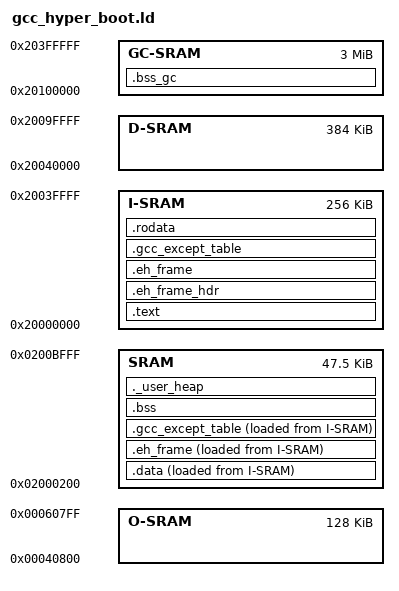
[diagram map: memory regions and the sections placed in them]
/*
 * Copyright (C) 2017-2019 Alibaba Group Holding Limited
 */

/******************************************************************************
 * @file     gcc_csky.ld
 * @brief    csky linker file
 * @version  V1.0
 * @date     02. June 2017
 ******************************************************************************/
MEMORY
{
	I-SRAM : ORIGIN = 0x20000000 , LENGTH = 0x40000   /* I-SRAM  128KB */
	D-SRAM : ORIGIN = 0x20040000 , LENGTH = 0x60000   /* D-SRAM  128KB */
	GC-SRAM : ORIGIN = 0x20100000 , LENGTH = 0x300000   /* GC-SRAM  3MB */
	O-SRAM : ORIGIN = 0x40800 , LENGTH = 0x20000   /* off-chip SRAM 8MB */
	SRAM   : ORIGIN = 0x02000200 , LENGTH = 0xBE00   /* on-chip SRAM 128KB */
}

__min_heap_size = 0x0000;

REGION_ALIAS("REGION_TEXT",    I-SRAM);
REGION_ALIAS("REGION_RODATA",  I-SRAM);
REGION_ALIAS("REGION_DATA",    SRAM);
REGION_ALIAS("REGION_BSS",     SRAM);
REGION_ALIAS("REGION_GC",      GC-SRAM);

ENTRY(Reset_Handler)
SECTIONS
{
 .text : {
  . = ALIGN(0x4) ;
  KEEP(*startup.o(*.text*))
  KEEP (*(SORT(.version)))
  KEEP (*(SORT(.compiledate)))
  KEEP (*(SORT(.compiletime)))
  . = ALIGN(0x4) ;
  __stext = . ;
  *(.text)
  *(.text*)
  *(.text.*)
  *(.gnu.warning)
  *(.stub)
  *(.gnu.linkonce.t*)
  *(.glue_7t)
  *(.glue_7)
  *(.jcr)
  KEEP (*(.init))
  KEEP (*(.fini))
  . = ALIGN (4) ;
  PROVIDE(__ctbp = .);
  *(.call_table_data)
  *(.call_table_text)
  . = ALIGN(0x10) ;
  __etext = . ;
  /* section information for usbh class */
  . = ALIGN(4);
  __usbh_class_info_start__ = .;
  KEEP(*(.usbh_class_info))
  __usbh_class_info_end__ = .;
 } > REGION_TEXT
 .eh_frame_hdr : {
  *(.eh_frame_hdr)
 } > REGION_TEXT
 .eh_frame : ONLY_IF_RO {
  KEEP (*(.eh_frame))
 } > REGION_TEXT
 .gcc_except_table : ONLY_IF_RO {
  *(.gcc_except_table .gcc_except_table.*)
 } > REGION_TEXT
 .rodata : {
  . = ALIGN(0x4) ;
  __srodata = .;
  *(.rdata)
  *(.rdata*)
  *(.rdata1)
  *(.rdata.*)
  *(.rodata)
  *(.rodata1)
  *(.rodata*)
  *(.rodata.*)
  *(.rodata.str1.4)
  *(.srodata*)
  . = ALIGN(0x4) ;
  __ctor_start__ = .;
  KEEP (*(SORT(.ctors.*)))
  KEEP (*(.ctors))
  __ctor_end__ = .;
  KEEP (*(SORT(.dtors.*)))
  KEEP (*(.dtors))
  __dtor_end__ = .;
  . = ALIGN(0x4) ;
  __erodata = .;
  __rodata_end__ = .;
 } > REGION_RODATA
 .data : {
  . = ALIGN(0x4) ;
  __sdata = . ;
  __data_start__ = . ;
  data_start = . ;
  KEEP(*startup.o(*.vectors*))
  *(.got.plt)
  *(.got)
  *(.gnu.linkonce.r*)
  *(.data)
  *(.data*)
  *(.data1)
  *(.data.*)
  *(.gnu.linkonce.d*)
  *(.data1)
  *(.gcc_except_table)
  *(.gcc_except_table*)
  __start_init_call = .;
  *(.initcall.init)
  __stop_init_call = .;
  __start_cmd = .;
  *(.bootloaddata.cmd)
  . = ALIGN(4) ;
  __stop_cmd = .;
  __global_pointer$ = .;
  *(.sdata)
  *(.sdata.*)
  *(.sdata2.*)
  *(.gnu.linkonce.s.*)
  *(__libc_atexit)
  *(__libc_subinit)
  *(__libc_subfreeres)
  *(.note.ABI-tag)
  __edata = .;
  __data_end__ = .;
  . = ALIGN(0x4) ;
 } > REGION_DATA AT > REGION_RODATA
 .eh_frame : ONLY_IF_RW {
  KEEP (*(.eh_frame))
 } > REGION_DATA AT > REGION_RODATA
 .gcc_except_table : ONLY_IF_RW {
  *(.gcc_except_table .gcc_except_table.*)
  __edata = .;
  __data_end__ = .;
 } > REGION_DATA AT > REGION_RODATA
 .bss : {
  . = ALIGN(0x4) ;
  __sbss = ALIGN(0x4) ;
  __bss_start__ = . ;
  *(.dynsbss)
  *(.sbss)
  *(.sbss.*)
  *(.scommon)
  *(.dynbss)
  *(.bss)
  *(.bss.*)
  *(COMMON)
  . = ALIGN(0x4) ;
  __ebss = . ;
  __bss_end__ = .;
  __end = . ;
  end = . ;
 } > REGION_BSS AT > REGION_BSS
 ._user_heap : {
  . = ALIGN(0x4) ;
  __heap_start = .;
  . += __min_heap_size;
  . = ALIGN(0x4) ;
  __heap_end = .;
 } > REGION_BSS AT > REGION_BSS
 
 .bss_gc   (NOLOAD)         :
  {
    *(.gcheap)
  } >REGION_GC AT>REGION_GC
}
